VERSION "HIPBYYYYYYYYYYYYYYYYYYYYYYYYYYYYNNNNNNNNNN/4/%%%/4/'%**4NNN///"

NS_ :

BS_:

BU_: ADMM_05429 ADMM_05431 ADMM_05432 CSM_GmbH

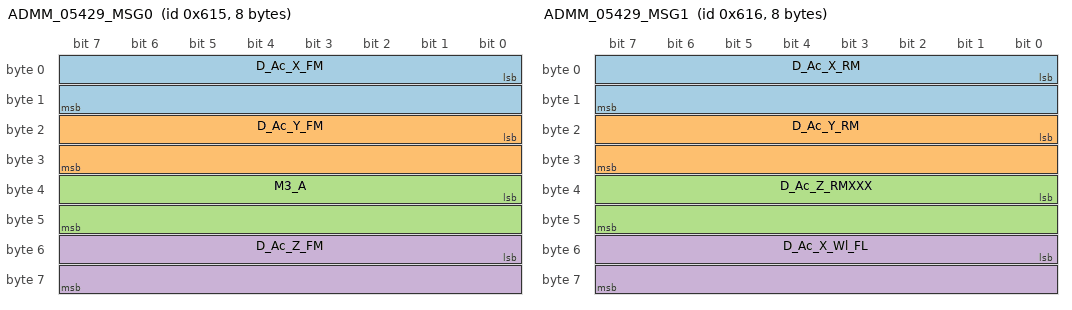
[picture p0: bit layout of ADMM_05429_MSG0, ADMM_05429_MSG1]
BO_ 1557 ADMM_05429_MSG0: 8 ADMM_05429
 SG_ D_Ac_X_FM : 0|16@1- (-0.00228603067,0) [-50|50] "g" CSM_GmbH
 SG_ D_Ac_Y_FM : 16|16@1- (-0.00230328374,0) [-50|50] "g" CSM_GmbH
 SG_ M3_A : 32|16@1- (0.00061037019,0) [-20|20] "V" CSM_GmbH
 SG_ D_Ac_Z_FM : 48|16@1- (0.00229462477,0) [-50|50] "g" CSM_GmbH

BO_ 1558 ADMM_05429_MSG1: 8 ADMM_05429
 SG_ D_Ac_X_RM : 0|16@1- (-0.00153051703,0) [-50|50] "g" CSM_GmbH
 SG_ D_Ac_Y_RM : 16|16@1- (-0.00153359344,0) [-50|50] "g" CSM_GmbH
 SG_ D_Ac_Z_RMXXX : 32|16@1- (0.00152287972,0) [-50|50] "g" CSM_GmbH
 SG_ D_Ac_X_Wl_FL : 48|16@1- (0.0061529253,0) [-200|200] "g" CSM_GmbH

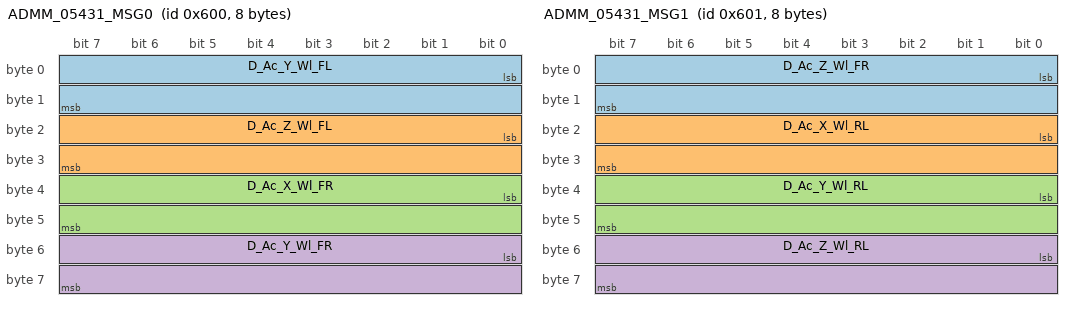
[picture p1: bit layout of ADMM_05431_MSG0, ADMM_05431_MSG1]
BO_ 1536 ADMM_05431_MSG0: 8 ADMM_05431
 SG_ D_Ac_Y_Wl_FL : 0|16@1- (-0.00619665168,0) [-200|200] "g" CSM_GmbH
 SG_ D_Ac_Z_Wl_FL : 16|16@1- (0.00604925857,0) [-200|200] "g" CSM_GmbH
 SG_ D_Ac_X_Wl_FR : 32|16@1- (0.00628082105,0) [-200|200] "g" CSM_GmbH
 SG_ D_Ac_Y_Wl_FR : 48|16@1- (-0.00612022651,0) [-200|200] "g" CSM_GmbH

BO_ 1537 ADMM_05431_MSG1: 8 ADMM_05431
 SG_ D_Ac_Z_Wl_FR : 0|16@1- (0.00625763984,0) [-200|200] "g" CSM_GmbH
 SG_ D_Ac_X_Wl_RL : 16|16@1- (0.0092200935,0) [-200|200] "g" CSM_GmbH
 SG_ D_Ac_Y_Wl_RL : 32|16@1- (-0.0091784991,0) [-200|200] "g" CSM_GmbH
 SG_ D_Ac_Z_Wl_RL : 48|16@1- (-0.0092200935,0) [-200|200] "g" CSM_GmbH

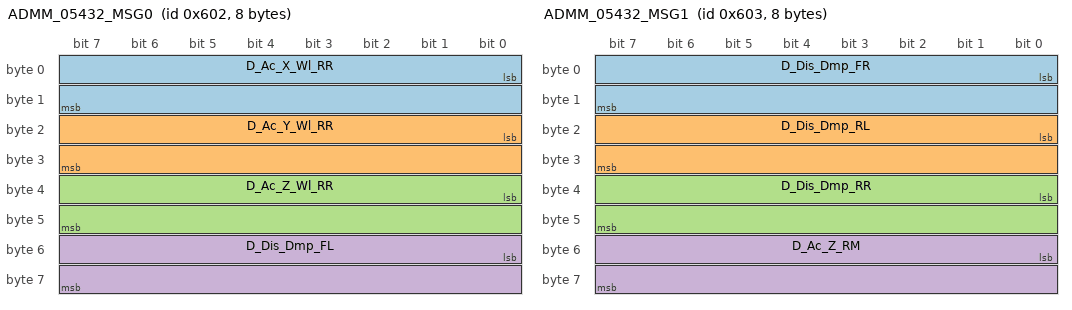
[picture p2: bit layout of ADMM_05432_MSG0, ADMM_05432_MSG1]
BO_ 1538 ADMM_05432_MSG0: 8 ADMM_05432
 SG_ D_Ac_X_Wl_RR : 0|16@1- (0.00916471757,0) [-200|200] "g" CSM_GmbH
 SG_ D_Ac_Y_Wl_RR : 16|16@1- (0.00924803318,0) [-200|200] "g" CSM_GmbH
 SG_ D_Ac_Z_Wl_RR : 32|16@1- (0.00919232214,0) [-200|200] "g" CSM_GmbH
 SG_ D_Dis_Dmp_FL : 48|16@1- (0.0366222114,0) [-600|600] "mm" CSM_GmbH

BO_ 1539 ADMM_05432_MSG1: 8 ADMM_05432
 SG_ D_Dis_Dmp_FR : 0|16@1- (0.0366222114,0) [-600|600] "mm" CSM_GmbH
 SG_ D_Dis_Dmp_RL : 16|16@1- (0.0732444228,0) [-600|600] "mm" CSM_GmbH
 SG_ D_Dis_Dmp_RR : 32|16@1- (0.0366222114,0) [-600|600] "mm" CSM_GmbH
 SG_ D_Ac_Z_RM : 48|16@1- (0.00152287972,0) [-50|50] "g" CSM_GmbH

CM_ BU_ ADMM_05429 "CSM = 3, MiniModulAD, 0, 8, 0x615, 0, 5429, 2, -ADMD, 1089, 0, 0, 0, 0, 15, 0x44303030, 4, 0x1, Hash(3184888539)";
CM_ BU_ ADMM_05431 "CSM = 3, MiniModulAD, 0, 8, 0x600, 0, 5431, 2, -ADMD, 1089, 0, 0, 0, 0, 15, 0x44303030, 4, 0x1, Hash(806198374)";
CM_ BU_ ADMM_05432 "CSM = 3, MiniModulAD, 0, 8, 0x602, 0, 5432, 2, -ADMD, 1089, 0, 0, 0, 0, 15, 0x44303030, 4, 0x1, Hash(2405168736)";
BA_DEF_  "BusType" STRING ;
BA_DEF_  "CSMconfigVersion" STRING ;
BA_DEF_  "CSMformatVersion" INT 0 255 ;
BA_DEF_ BU_ "CSMdeviceType" INT -1 3003 ;
BA_DEF_  "CSMdata0000" STRING ;
BA_DEF_  "CSMdata0001" STRING ;
BA_DEF_  "CSMdata0002" STRING ;
BA_DEF_  "CSMdata0003" STRING ;
BA_DEF_  "CSMdata0004" STRING ;
BA_DEF_  "CSMdata0005" STRING ;
BA_DEF_  "CSMdata0006" STRING ;
BA_DEF_  "CSMdata0007" STRING ;
BA_DEF_  "CSMdata0008" STRING ;
BA_DEF_  "CSMdata0009" STRING ;
BA_DEF_  "CSMdata0010" STRING ;
BA_DEF_  "CSMdata0011" STRING ;

BA_DEF_DEF_ "BusType" "";
BA_DEF_DEF_ "CSMconfigVersion" "";
BA_DEF_DEF_ "CSMformatVersion" 0 ;
BA_DEF_DEF_ "CSMdeviceType" -1 ;
BA_DEF_DEF_ "CSMdata0000" "";
BA_DEF_DEF_ "CSMdata0001" "";
BA_DEF_DEF_ "CSMdata0002" "";
BA_DEF_DEF_ "CSMdata0003" "";
BA_DEF_DEF_ "CSMdata0004" "";
BA_DEF_DEF_ "CSMdata0005" "";
BA_DEF_DEF_ "CSMdata0006" "";
BA_DEF_DEF_ "CSMdata0007" "";
BA_DEF_DEF_ "CSMdata0008" "";
BA_DEF_DEF_ "CSMdata0009" "";
BA_DEF_DEF_ "CSMdata0010" "";
BA_DEF_DEF_ "CSMdata0011" "";

BA_ "BusType"  "CAN";
BA_ "CSMconfigVersion"  "8.6.1.6787";
BA_ "CSMformatVersion"  2 ;
BA_ "CSMdeviceType" BU_ ADMM_05429 4 ;
BA_ "CSMdeviceType" BU_ ADMM_05431 4 ;
BA_ "CSMdeviceType" BU_ ADMM_05432 4 ;
BA_ "CSMdata0000"  "9F040000B32C00006BBBF70178DAED5ADD6FDB3610DF7381FE0F9C9E36B49628595F0E1C1741DC0003E22EB083CDED8B414BB44D40223591FEDA5FBF23E5D889BB6E713A21CD2ABD88A48EC7BBFBDD1D75A2BAEF36798656B4944CF073CBB5B1F5AEF7FA";
BA_ "CSMdata0001"  "55F7723448049FB139AA6E7B8AD80E6DD70EA338B2D04C943951FB479E85801997671BC9CEAD8552C599E3ACD76B7BDDB64539773C8C5D673CB81E250B9A9316E352119E509825D9993483D72221CA30BB373D91B99D52E720D2BE656F646AF5BA3FB65A";
BA_ "CSMdata0002"  "E81760DCFF75D017C932A75C9D9D2525258ABECFA8EEFEF4334A0595880B851684A719459CE454162481D14494254D948D5AAD8AD9ED829614B4A36F915A50B45E089890EE582306330CF314AD995A88A5420455F22398065341AB03B32B51A215C9580A";
BA_ "CSMdata0003"  "9AF1F95B546494488A489A1AE6339165620D4F0E121DE61A7BFEA3312C437B79F161BA9488299ACF323287296D0B4D992A41CA732BC0FA02BC4A58416D0B18725D0B4992832C85605C9D5B61682196329E80A8F0D84239918A962C3DB7FC28E8789EDF76";
BA_ "CSMdata0004"  "C1D47DBA6260B2BBC6D18A295D55EC7DD35E919211CDDC0D60355A7201B2F85EC73CD41D90A9D26241E40238B8B11FC771D0068A82960920C569565168E25EF70328D0BBE80F0613AC19751D33B013E6A614854492D30D2CD902AABE8516EB92AEB4BABE";
BA_ "CSMdata0005"  "8F711C05E0A3B335782C0CE11896494841A62C638A5150C1F3621C6BF9644113A60DE15B8EB1AEA44AA3279F62D429C0AD6D1044BA07562D8CE6F7AD0D8BDC9684CB9C2954B10741A75B4545996A6135399F895C1A3B68912ADBC87DEB0889645189B437";
BA_ "CSMdata0006"  "5A7F72914CC693ABC19DCD2E45AEBDB9D775F6AD11E572B42C8A6C8B562253640E0CDEB866BD51021ECCE7B76B71A355431B0C8F40AA8D0BA6C636F6C208DFBF40FCED8E64EB6A2E165A72062601874D992C32B2CD1984792BC08701B201CAC0AC37247C";
BA_ "CSMdata0007"  "4EC114DCC800DC4C73CA0A5179A7E9561C0DFD15CBC05BD1CCDC766858BBEEACA47F40E2D26801E5A7CBC10DFA9396221139049B622B63A6FD90F6784378FBBE3F02DF53A5C8AAF8BDF3570EB98256BDCA6F0DB9B303E234443ED68888DF79703588FC1B";
BA_ "CSMdata0008"  "2283F6E4E2ABC0B8669C12D0199410A5B6B50D2A862E6E47D8EDDC8506E442319B4142A9C0A84CF6DB1108DE3108DEDF8180FFB771F1A996B87863E22268E2E209888C27C39A3255BB13470D224FD93B6A44A4D9CD9F94B58683F1785C4FE28217D80761";
BA_ "CSMdata0009"  "1237A03C3271FD9E4DAEAEEB0105773A8F0E0E0F7FBEA9BF78249C4325E25465D8D7D48650637EA1368CE13DAA13B723FF51A561DB7D59A5613B7CEED2F0635D51D23251123F2C46FCEF3A664EDB526ACC5E2E20D32071D23E32AC6B1F89DC07BBBBD7E0";
BA_ "CSMdata0010"  "7252E61AD695B93A91D7E0F2F4CC555FBC04FEFD1225687039258F0DEB7A1F0EC326424ECA5CC3BADEB9C2A30FC05183CB2999AB465C9A8AF13FAC18BD2F558C9E8F03378C235D5B3DA664F45E58C9183FFF69A20E93616D1B49F8E01BA4DBA4AF93B695";
BA_ "CSMdata0011"  "FA70698038691FA90F08BF0990D371E93339E9E7453DDF545C7C044288F747BC797E8443F8190E21FE8E4E79F7400C1B20BE09206AA90983068793716802E29B38C96D8E719FA31474F6BF983AD55FADBA71F7B76BEFF5AB1FFE0268340DD6";
